# EFR32FG23B010F512IM48 register map
Vendor: Silicon Labs; Series: EFR32; File version: C
CPU: CM33 r0p4, little endian, MPU, FPU, DSP, VTOR, 4 interrupt priority bits, 8 SAU regions
Registers are 32-bit, read-write, reset 0x0 unless marked. A register's access mark holds for its fields unless they carry their own. Offsets are from the block's base; [hi:lo] are bit positions.

## LETIMER0_NS — LETIMER0_NS Registers
Base 0x59000000
Same registers: LETIMER0_S 0x49000000
0x00 IPVERSION ro reset 0x1
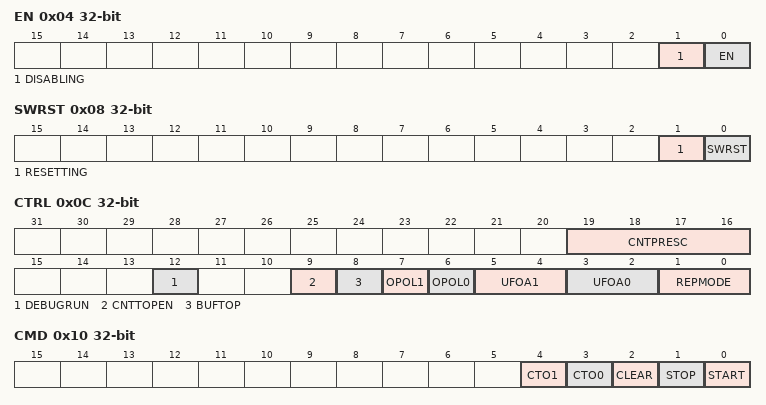
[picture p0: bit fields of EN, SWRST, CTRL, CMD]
0x04 EN
  [1] DISABLING ro — Disablement busy status
  [0] EN — module en
0x08 SWRST
  [1] RESETTING ro — Software reset busy status
  [0] SWRST wo — Software reset command
0x0C CTRL
  [19:16] CNTPRESC — Counter prescaler value
    0=DIV1 (CLK_CNT = (LETIMER LF CLK)/1); 1=DIV2 (CLK_CNT = (LETIMER LF CLK)/2); 2=DIV4 (CLK_CNT = (LETIMER LF CLK)/4); 3=DIV8 (CLK_CNT = (LETIMER LF CLK)/8); 4=DIV16 (CLK_CNT = (LETIMER LF CLK)/16); 5=DIV32 (CLK_CNT = (LETIMER LF CLK)/32); 6=DIV64 (CLK_CNT = (LETIMER LF CLK)/64); 7=DIV128 (CLK_CNT = (LETIMER LF CLK)/128); 8=DIV256 (CLK_CNT = (LETIMER LF CLK)/256)
  [12] DEBUGRUN — Debug Mode Run Enable
    0=DISABLE (LETIMER is frozen in debug mode); 1=ENABLE (LETIMER is running in debug mode)
  [9] CNTTOPEN — Compare Value 0 Is Top Value
    0=DISABLE (The top value of the LETIMER is 65535 (0xFFFF)); 1=ENABLE (The top value of the LETIMER is given by TOP)
  [8] BUFTOP — Buffered Top
    0=DISABLE (TOP is only written by software); 1=ENABLE (TOP is set to TOPBUFF value when REP0 reaches 0)
  [7] OPOL1 — Output 1 Polarity
  [6] OPOL0 — Output 0 Polarity
  [5:4] UFOA1 — Underflow Output Action 1
    0=NONE (LETIMERn_OUT1 is held at its idle value as defined by OPOL1); 1=TOGGLE (LETIMERn_OUT1 is toggled on CNT underflow); 2=PULSE (LETIMERn_OUT1 is held active for one LETIMER0 clock cycle on CNT underflow. The output then returns to its idle value as defined by OPOL1); 3=PWM (LETIMERn_OUT1 is set idle on CNT underflow, and active on compare match with COMP1)
  [3:2] UFOA0 — Underflow Output Action 0
    0=NONE (LETIMERn_OUT0 is held at its idle value as defined by OPOL0); 1=TOGGLE (LETIMERn_OUT0 is toggled on CNT underflow); 2=PULSE (LETIMERn_OUT0 is held active for one LETIMER0 clock cycle on CNT underflow. The output then returns to its idle value as defined by OPOL0); 3=PWM (LETIMERn_OUT0 is set idle on CNT underflow, and active on compare match with COMP0)
  [1:0] REPMODE — Repeat Mode
    0=FREE (When started, the LETIMER counts down until it is stopped by software); 1=ONESHOT (The counter counts REP0 times. When REP0 reaches zero, the counter stops); 2=BUFFERED (The counter counts REP0 times. If REP1 has been written, it is loaded into REP0 when REP0 reaches zero, otherwise the counter stops); 3=DOUBLE (Both REP0 and REP1 are decremented when the LETIMER wraps around. The LETIMER counts until both REP0 and REP1 are zero)
0x10 CMD wo
  [4] CTO1 — Clear Toggle Output 1
  [3] CTO0 — Clear Toggle Output 0
  [2] CLEAR — Clear LETIMER
  [1] STOP — Stop LETIMER
  [0] START — Start LETIMER
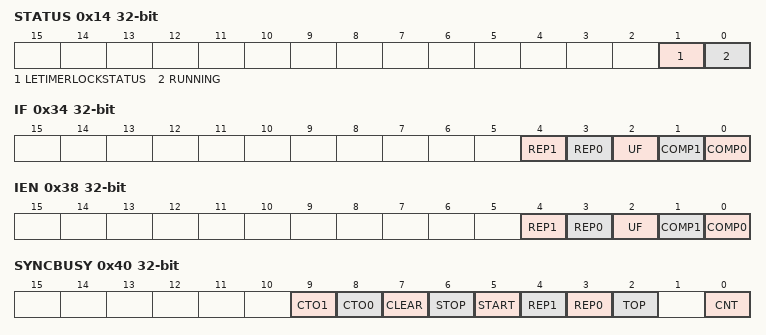
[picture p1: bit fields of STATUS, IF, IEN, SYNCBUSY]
0x14 STATUS ro
  [1] LETIMERLOCKSTATUS
    0=UNLOCKED (LETIMER registers are unlocked); 1=LOCKED (LETIMER registers are locked)
  [0] RUNNING — LETIMER Running
0x18 CNT
  [23:0] CNT — Counter Value
0x1C COMP0
  [23:0] COMP0 — Compare Value 0
0x20 COMP1
  [23:0] COMP1 — Compare Value 1
0x24 TOP
  [23:0] TOP — Counter TOP Value
0x28 TOPBUFF
  [23:0] TOPBUFF — Buffered Counter TOP Value
0x2C REP0
  [7:0] REP0 — Repeat Counter 0
0x30 REP1
  [7:0] REP1 — Repeat Counter 1
0x34 IF
  [4] REP1 — Repeat Counter 1 Interrupt Flag
  [3] REP0 — Repeat Counter 0 Interrupt Flag
  [2] UF — Underflow Interrupt Flag
  [1] COMP1 — Compare Match 1 Interrupt Flag
  [0] COMP0 — Compare Match 0 Interrupt Flag
0x38 IEN
  [4] REP1 — Repeat Counter 1 Interrupt Enable
  [3] REP0 — Repeat Counter 0 Interrupt Enable
  [2] UF — Underflow Interrupt Enable
  [1] COMP1 — Compare Match 1 Interrupt Enable
  [0] COMP0 — Compare Match 0 Interrupt Enable
0x3C LOCK wo
  [15:0] LETIMERLOCKKEY — Configuration Lock Key
    0xCCFC=UNLOCK (Write to unock LETIMER lockable registers)
0x40 SYNCBUSY ro
  [9] CTO1 — Sync busy for CTO1
  [8] CTO0 — Sync busy for CTO0
  [7] CLEAR — Sync busy for CLEAR
  [6] STOP — Sync busy for STOP
  [5] START — Sync busy for START
  [4] REP1 — Sync busy for REP1
  [3] REP0 — Sync busy for REP0
  [2] TOP — Sync busy for TOP
  [0] CNT — Sync busy for CNT
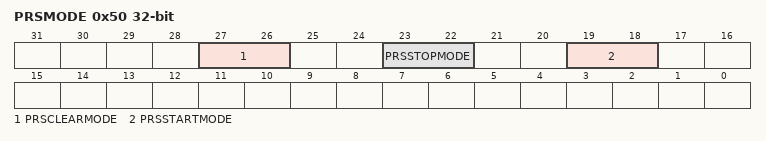
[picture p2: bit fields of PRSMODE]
0x50 PRSMODE
  [27:26] PRSCLEARMODE
    0=NONE (PRS cannot clear the LETIMER); 1=RISING (Rising edge of selected PRS input can clear the LETIMER); 2=FALLING (Falling edge of selected PRS input can clear the LETIMER); 3=BOTH (Both the rising or falling edge of the selected PRS input can clear the LETIMER)
  [23:22] PRSSTOPMODE
    0=NONE (PRS cannot stop the LETIMER); 1=RISING (Rising edge of selected PRS input can stop the LETIMER); 2=FALLING (Falling edge of selected PRS input can stop the LETIMER); 3=BOTH (Both the rising or falling edge of the selected PRS input can stop the LETIMER)
  [19:18] PRSSTARTMODE
    0=NONE (PRS cannot start the LETIMER); 1=RISING (Rising edge of selected PRS input can start the LETIMER); 2=FALLING (Falling edge of selected PRS input can start the LETIMER); 3=BOTH (Both the rising or falling edge of the selected PRS input can start the LETIMER)
